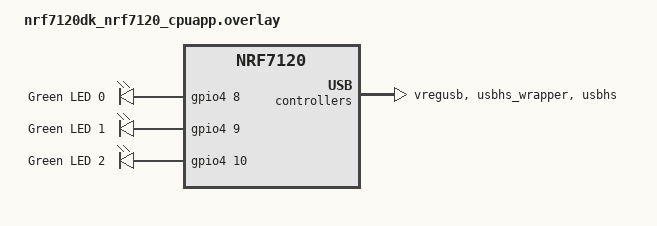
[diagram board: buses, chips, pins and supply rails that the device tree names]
/*
 * Copyright (c) 2026 Nordic Semiconductor ASA
 *
 * SPDX-License-Identifier: LicenseRef-Nordic-5-Clause
 */

#include "common/usb_audio.dtsi"

/ {
	audioleds: audioleds {
		compatible = "gpio-leds";
		status = "okay";

		led_conn_status: led_conn_status {
			gpios = <&gpio4 8 GPIO_ACTIVE_HIGH>;
			label = "Green LED 0";
		};

		led_sync_status: led_sync_status {
			gpios = <&gpio4 9 GPIO_ACTIVE_HIGH>;
			label = "Green LED 1";
		};

		led_app_status: led_app_status {
			gpios = <&gpio4 10 GPIO_ACTIVE_HIGH>;
			label = "Green LED 2";
		};
	};
};

&vregusb {
	status = "okay";
};

&usbhs_wrapper {
	status = "okay";
};

zephyr_udc0: &usbhs {
	status = "okay";
};
